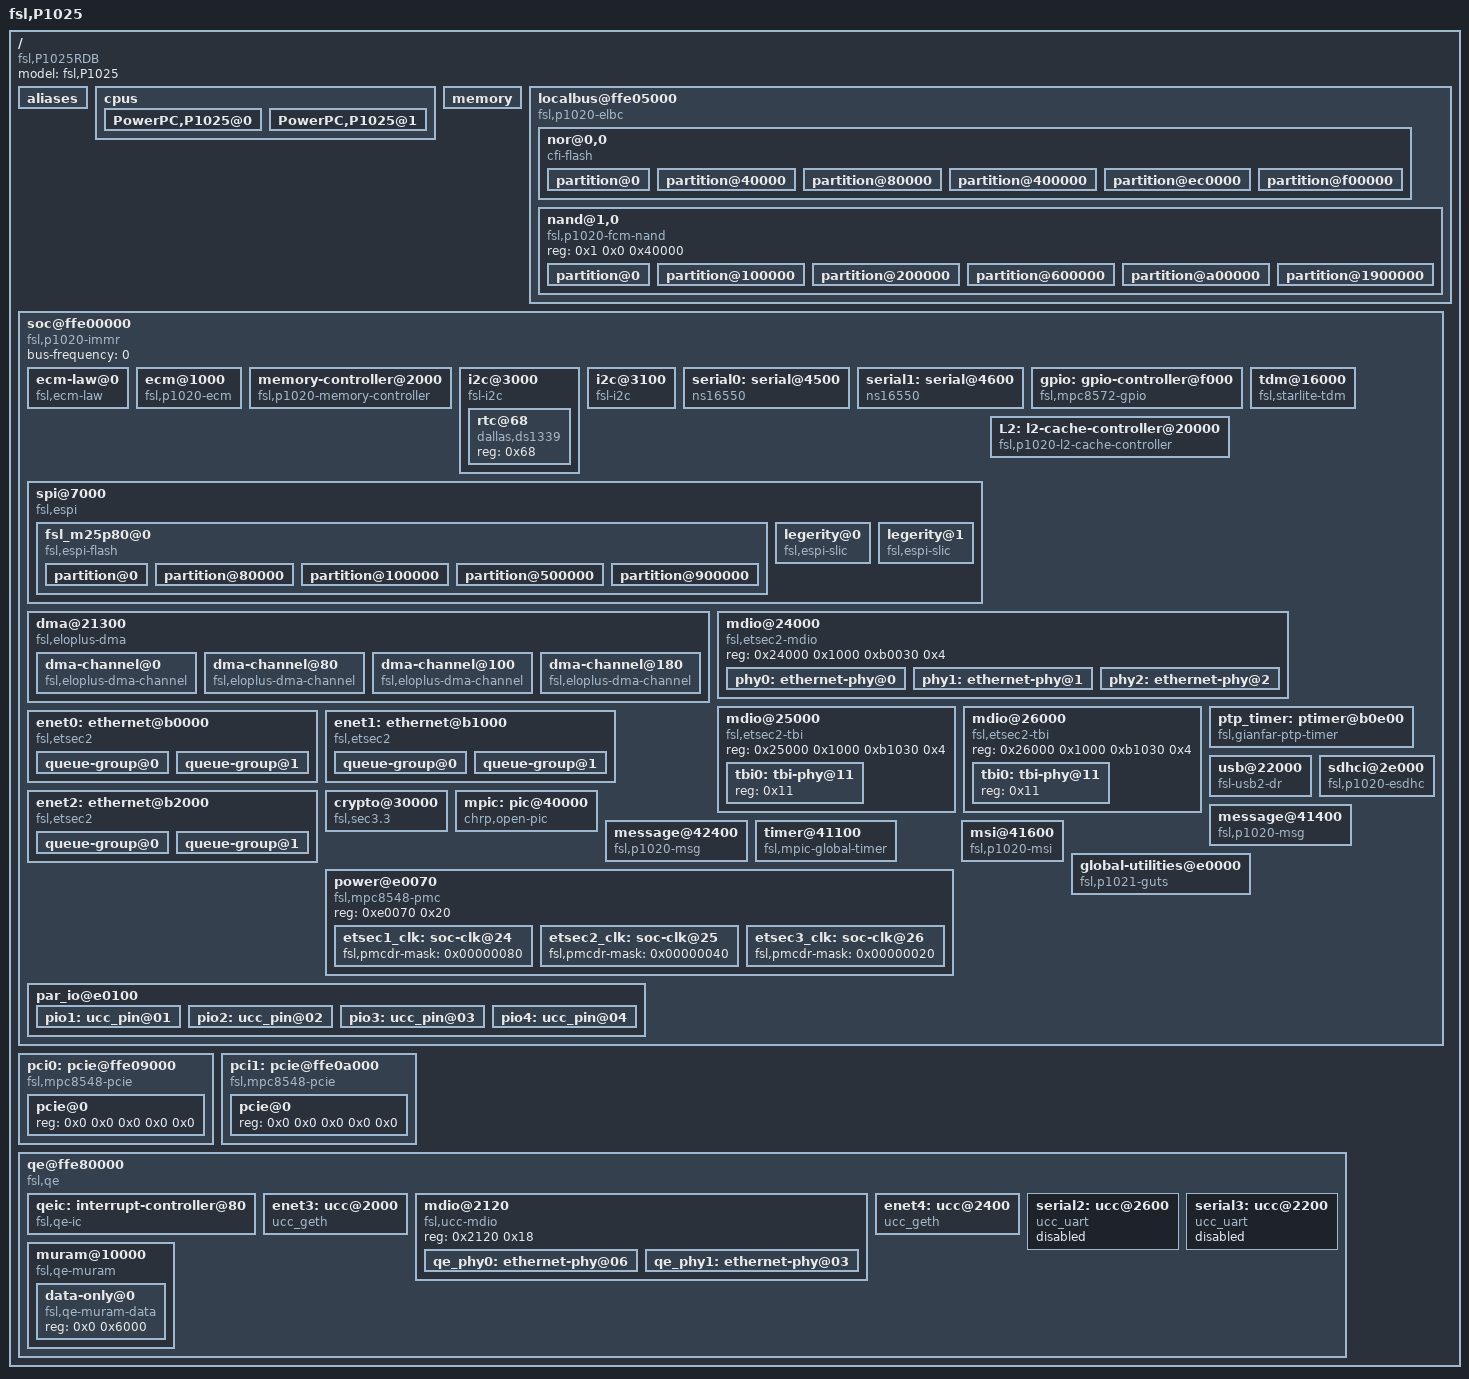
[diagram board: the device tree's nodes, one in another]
/*
 * P1025 RDB Device Tree Source
 *
 * Copyright 2009-2011 Freescale Semiconductor Inc.
 *
 * This program is free software; you can redistribute  it and/or modify it
 * under  the terms of  the GNU General  Public License as published by the
 * Free Software Foundation;  either version 2 of the  License, or (at your
 * option) any later version.
 */

/dts-v1/;
/ {
	model = "fsl,P1025";
	compatible = "fsl,P1025RDB";
	#address-cells = <2>;
	#size-cells = <2>;

	aliases {
		serial0 = &serial0;
		serial1 = &serial1;
		serial2 = &serial2;
		serial3 = &serial3;
		ethernet0 = &enet0;
		ethernet1 = &enet1;
		ethernet2 = &enet2;
		ethernet3 = &enet3;
		ethernet4 = &enet4;
		pci0 = &pci0;
		pci1 = &pci1;
	};

	cpus {
		#address-cells = <1>;
		#size-cells = <0>;

		PowerPC,P1025@0 {
			device_type = "cpu";
			reg = <0x0>;
			next-level-cache = <&L2>;
		};

		PowerPC,P1025@1 {
			device_type = "cpu";
			reg = <0x1>;
			next-level-cache = <&L2>;
		};
	};

	memory {
		device_type = "memory";
	};

	localbus@ffe05000 {
		#address-cells = <2>;
		#size-cells = <1>;
		compatible = "fsl,p1020-elbc", "fsl,elbc", "simple-bus";
		reg = <0 0xffe05000 0 0x1000>;
		interrupts = <19 2>;
		interrupt-parent = <&mpic>;

		/* NOR, NAND Flashes and Vitesse 5 port L2 switch */
		ranges = <0x0 0x0 0x0 0xef000000 0x01000000
			  0x1 0x0 0x0 0xff800000 0x00040000>;

		nor@0,0 {
			#address-cells = <1>;
			#size-cells = <1>;
			compatible = "cfi-flash";
			reg = <0x0 0x0 0x1000000>;
			bank-width = <2>;
			device-width = <1>;

			partition@0 {
				/* This location must not be altered  */
				/* 256KB for Vitesse 7385 Switch firmware */
				reg = <0x0 0x00040000>;
				label = "NOR Vitesse-7385 Firmware";
				read-only;
			};

			partition@40000 {
				/* 256KB for DTB Image */
				reg = <0x00040000 0x00040000>;
				label = "NOR DTB Image";
			};

			partition@80000 {
				/* 3.5 MB for Linux Kernel Image */
				reg = <0x00080000 0x00380000>;
				label = "NOR Linux Kernel Image";
			};

			partition@400000 {
				/* 10.75MB for JFFS2 based Root file System */
				reg = <0x00400000 0x00ac0000>;
				label = "NOR JFFS2 Root File System";
			};

			partition@ec0000 {
				/* 256KB for QE microcode image */
				reg = <0x00ec0000 0x00040000>;
				label = "Quicc Engine Microcode Image";
				read-only;
			};

			partition@f00000 {
				/* This location must not be altered  */
				/* 512KB for u-boot Bootloader Image */
				/* 512KB for u-boot Environment Variables */
				reg = <0x00f00000 0x00100000>;
				label = "NOR U-Boot Image";
				read-only;
			};
		};

		nand@1,0 {
			#address-cells = <1>;
			#size-cells = <1>;
			compatible = "fsl,p1020-fcm-nand",
				     "fsl,elbc-fcm-nand";
			reg = <0x1 0x0 0x40000>;

			partition@0 {
				/* This location must not be altered  */
				/* 1MB for u-boot Bootloader Image */
				reg = <0x0 0x00100000>;
				label = "NAND U-Boot Image";
				read-only;
			};

			partition@100000 {
				/* 1MB for DTB Image */
				reg = <0x00100000 0x00100000>;
				label = "NAND DTB Image";
			};

			partition@200000 {
				/* 4MB for Linux Kernel Image */
				reg = <0x00200000 0x00400000>;
				label = "NAND Linux Kernel Image";
			};

			partition@600000 {
				/* 4MB for Compressed Root file System Image */
				reg = <0x00600000 0x00400000>;
				label = "NAND Compressed RFS Image";
			};

			partition@a00000 {
				/* 15MB for JFFS2 based Root file System */
				reg = <0x00a00000 0x00f00000>;
				label = "NAND JFFS2 Root File System";
			};

			partition@1900000 {
				/* 7MB for User Writable Area */
				reg = <0x01900000 0x00700000>;
				label = "NAND Writable User area";
			};
		};

	};

	soc@ffe00000 {
		#address-cells = <1>;
		#size-cells = <1>;
		device_type = "soc";
		compatible = "fsl,p1020-immr", "simple-bus";
		ranges = <0x0  0x0 0xffe00000 0x100000>;
		bus-frequency = <0>;		// Filled out by uboot.

		ecm-law@0 {
			compatible = "fsl,ecm-law";
			reg = <0x0 0x1000>;
			fsl,num-laws = <12>;
		};

		ecm@1000 {
			compatible = "fsl,p1020-ecm", "fsl,ecm";
			reg = <0x1000 0x1000>;
			interrupts = <16 2>;
			interrupt-parent = <&mpic>;
		};

		memory-controller@2000 {
			compatible = "fsl,p1020-memory-controller";
			reg = <0x2000 0x1000>;
			interrupt-parent = <&mpic>;
			interrupts = <16 2>;
		};

		i2c@3000 {
			#address-cells = <1>;
			#size-cells = <0>;
			compatible = "fsl-i2c";
			reg = <0x3000 0x100>;
			interrupts = <43 2>;
			interrupt-parent = <&mpic>;
			dfsrr;
			rtc@68 {
				compatible = "dallas,ds1339";
				reg = <0x68>;
			};
		};

		i2c@3100 {
			#address-cells = <1>;
			#size-cells = <0>;
			compatible = "fsl-i2c";
			reg = <0x3100 0x100>;
			interrupts = <43 2>;
			interrupt-parent = <&mpic>;
			dfsrr;
		};

		serial0: serial@4500 {
			device_type = "serial";
			compatible = "ns16550";
			reg = <0x4500 0x100>;
			clock-frequency = <0>;
			interrupts = <42 2>;
			interrupt-parent = <&mpic>;
		};

		serial1: serial@4600 {
			device_type = "serial";
			compatible = "ns16550";
			reg = <0x4600 0x100>;
			clock-frequency = <0>;
			interrupts = <42 2>;
			interrupt-parent = <&mpic>;
		};

		spi@7000 {
			cell-index = <0>;
			#address-cells = <1>;
			#size-cells = <0>;
			compatible = "fsl,espi";
			reg = <0x7000 0x1000>;
			interrupts = <59 0x2>;
			interrupt-parent = <&mpic>;
			espi,num-ss-bits = <4>;
			mode = "cpu";

			fsl_m25p80@0 {
				#address-cells = <1>;
				#size-cells = <1>;
				compatible = "fsl,espi-flash";
				reg = <0>;
				linux,modalias = "fsl_m25p80";
				spi-max-frequency = <40000000>;

				partition@0 {
					/* 512KB for u-boot Bootloader Image */
					reg = <0x0 0x00080000>;
					label = "SPI U-Boot Image";
					read-only;
				};

				partition@80000 {
					/* 512KB for DTB Image */
					reg = <0x00080000 0x00080000>;
					label = "SPI DTB Image";
				};

				partition@100000 {
					/* 4MB for Linux Kernel Image */
					reg = <0x00100000 0x00400000>;
					label = "SPI Linux Kernel Image";
				};

				partition@500000 {
					/* 4MB for Compressed RFS Image */
					reg = <0x00500000 0x00400000>;
					label = "SPI Compressed RFS Image";
				};

				partition@900000 {
					/* 7MB for JFFS2 based RFS */
					reg = <0x00900000 0x00700000>;
					label = "SPI JFFS2 RFS";
				};
			};

			legerity@0{
				compatible = "fsl,espi-slic";
				reg = <1>;
				linux,modalias = "legerity";
				spi-max-frequency = <8000000>;
				ch1-rx-slot = <0>;
				ch1-tx-slot = <0>;
				ch2-rx-slot = <2>;
				ch2-tx-slot = <2>;
			};

			legerity@1{
				compatible = "fsl,espi-slic";
				reg = <2>;
				linux,modalias = "legerity";
				spi-max-frequency = <8000000>;
				ch1-rx-slot = <4>;
				ch1-tx-slot = <4>;
				ch2-rx-slot = <6>;
				ch2-tx-slot = <6>;
			};
		};

		gpio: gpio-controller@f000 {
			#gpio-cells = <2>;
			compatible = "fsl,mpc8572-gpio";
			reg = <0xf000 0x100>;
			interrupts = <47 0x2>;
			interrupt-parent = <&mpic>;
			gpio-controller;
		};

		tdm@16000 {
			compatible = "fsl,starlite-tdm";
			reg = <0x16000 0x200 0x2c000 0x2000>;
			clock-frequency = <0>;
			interrupts = <63 8 62 8>;
			interrupt-parent = < &mpic >;
		};

		L2: l2-cache-controller@20000 {
			compatible = "fsl,p1020-l2-cache-controller";
			reg = <0x20000 0x1000>;
			cache-line-size = <32>;	// 32 bytes
			cache-size = <0x40000>; // L2,256K
			interrupt-parent = <&mpic>;
			interrupts = <16 2>;
		};

		dma@21300 {
			#address-cells = <1>;
			#size-cells = <1>;
			compatible = "fsl,eloplus-dma";
			reg = <0x21300 0x4>;
			ranges = <0x0 0x21100 0x200>;
			cell-index = <0>;
			dma-channel@0 {
				compatible = "fsl,eloplus-dma-channel";
				reg = <0x0 0x80>;
				cell-index = <0>;
				interrupt-parent = <&mpic>;
				interrupts = <20 2>;
			};
			dma-channel@80 {
				compatible = "fsl,eloplus-dma-channel";
				reg = <0x80 0x80>;
				cell-index = <1>;
				interrupt-parent = <&mpic>;
				interrupts = <21 2>;
			};
			dma-channel@100 {
				compatible = "fsl,eloplus-dma-channel";
				reg = <0x100 0x80>;
				cell-index = <2>;
				interrupt-parent = <&mpic>;
				interrupts = <22 2>;
			};
			dma-channel@180 {
				compatible = "fsl,eloplus-dma-channel";
				reg = <0x180 0x80>;
				cell-index = <3>;
				interrupt-parent = <&mpic>;
				interrupts = <23 2>;
			};
		};

		mdio@24000 {
			#address-cells = <1>;
			#size-cells = <0>;
			compatible = "fsl,etsec2-mdio";
			reg = <0x24000 0x1000 0xb0030 0x4>;

			phy0: ethernet-phy@0 {
				interrupt-parent = <&mpic>;
				interrupts = <3 1>;
				reg = <0x0>;
			};

			phy1: ethernet-phy@1 {
				interrupt-parent = <&mpic>;
				interrupts = <2 1>;
				reg = <0x1>;
			};
			phy2: ethernet-phy@2 {
				interrupt-parent = <&mpic>;
				interrupts = <1 1>;
				reg = <0x2>;
			};
		};

		mdio@25000 {
			#address-cells = <1>;
			#size-cells = <0>;
			compatible = "fsl,etsec2-tbi";
			reg = <0x25000 0x1000 0xb1030 0x4>;

			tbi0: tbi-phy@11 {
				reg = <0x11>;
				device_type = "tbi-phy";
			};
		};

		mdio@26000 {
			#address-cells = <1>;
			#size-cells = <0>;
			compatible = "fsl,etsec2-tbi";
			reg = <0x26000 0x1000 0xb1030 0x4>;

			tbi0: tbi-phy@11 {
				reg = <0x11>;
				device_type = "tbi-phy";
			};
		};

		ptp_timer: ptimer@b0e00 {
			compatible = "fsl,gianfar-ptp-timer";
			reg = <0xb0e00 0xb0>;
			interrupts = <68 2 69 2 70 2>;
			interrupt-parent = <&mpic>;
			tmr-prsc = <0x2>;
			cksel = <1>;
		};

		enet0: ethernet@b0000 {
			#address-cells = <1>;
			#size-cells = <1>;
			device_type = "network";
			model = "eTSEC";
			compatible = "fsl,etsec2";
			fsl,num_rx_queues = <0x8>;
			fsl,num_tx_queues = <0x8>;
			local-mac-address = [ 00 00 00 00 00 00 ];
			interrupt-parent = <&mpic>;
			fixed-link = <1 1 1000 0 0>;
			phy-handle = <&phy2>;
			phy-connection-type = "rgmii-id";
			ptimer-handle = <&ptp_timer>;
			fsl,magic-packet;
			clk-handle = <&etsec1_clk>;

			queue-group@0 {
				#address-cells = <1>;
				#size-cells = <1>;
				reg = <0xb0000 0x1000>;
				interrupts = <29 2 30 2 34 2>;
			};

			queue-group@1 {
				#address-cells = <1>;
				#size-cells = <1>;
				reg = <0xb4000 0x1000>;
				interrupts = <17 2 18 2 24 2>;
			};
		};

		enet1: ethernet@b1000 {
			#address-cells = <1>;
			#size-cells = <1>;
			device_type = "network";
			model = "eTSEC";
			compatible = "fsl,etsec2";
			fsl,num_rx_queues = <0x8>;
			fsl,num_tx_queues = <0x8>;
			local-mac-address = [ 00 00 00 00 00 00 ];
			interrupt-parent = <&mpic>;
			phy-handle = <&phy0>;
			tbi-handle = <&tbi0>;
			phy-connection-type = "sgmii";
			ptimer-handle = <&ptp_timer>;
			fsl,magic-packet;
			clk-handle = <&etsec2_clk>;

			queue-group@0 {
				#address-cells = <1>;
				#size-cells = <1>;
				reg = <0xb1000 0x1000>;
				interrupts = <35 2 36 2 40 2>;
			};

			queue-group@1 {
				#address-cells = <1>;
				#size-cells = <1>;
				reg = <0xb5000 0x1000>;
				interrupts = <51 2 52 2 67 2>;
			};
		};

		enet2: ethernet@b2000 {
			#address-cells = <1>;
			#size-cells = <1>;
			device_type = "network";
			model = "eTSEC";
			compatible = "fsl,etsec2";
			fsl,num_rx_queues = <0x8>;
			fsl,num_tx_queues = <0x8>;
			local-mac-address = [ 00 00 00 00 00 00 ];
			interrupt-parent = <&mpic>;
			phy-handle = <&phy1>;
			phy-connection-type = "rgmii-id";
			ptimer-handle = <&ptp_timer>;
			fsl,magic-packet;
			clk-handle = <&etsec3_clk>;

			queue-group@0 {
				#address-cells = <1>;
				#size-cells = <1>;
				reg = <0xb2000 0x1000>;
				interrupts = <31 2 32 2 33 2>;
			};

			queue-group@1 {
				#address-cells = <1>;
				#size-cells = <1>;
				reg = <0xb6000 0x1000>;
				interrupts = <25 2 26 2 27 2>;
			};
		};

		usb@22000 {
			#address-cells = <1>;
			#size-cells = <0>;
			compatible = "fsl-usb2-dr";
			reg = <0x22000 0x1000>;
			interrupt-parent = <&mpic>;
			interrupts = <28 0x2>;
			phy_type = "ulpi";
		};

		sdhci@2e000 {
			compatible = "fsl,p1020-esdhc", "fsl,esdhc";
			reg = <0x2e000 0x1000>;
			interrupts = <72 0x2>;
			interrupt-parent = <&mpic>;
			/* Filled in by U-Boot */
			clock-frequency = <0>;
		};

		crypto@30000 {
			compatible = "fsl,sec3.3", "fsl,sec3.1",
				     "fsl,sec3.0", "fsl,sec2.4",
				     "fsl,sec2.2", "fsl,sec2.1", "fsl,sec2.0";
			reg = <0x30000 0x10000>;
			interrupts = <45 2 58 2>;
			interrupt-parent = <&mpic>;
			fsl,num-channels = <4>;
			fsl,channel-fifo-len = <24>;
			fsl,exec-units-mask = <0x97c>;
			fsl,descriptor-types-mask = <0x3a30abf>;
			fsl,multi-host-mode = "dual";
			fsl,channel-remap = <0x3>;
		};

		mpic: pic@40000 {
			interrupt-controller;
			#address-cells = <0>;
			#interrupt-cells = <2>;
			reg = <0x40000 0x40000>;
			compatible = "chrp,open-pic";
			device_type = "open-pic";
		};

		message@41400 {
			compatible = "fsl,p1020-msg", "fsl,mpic-msg";
			reg = <0x41400 0x200>;
			interrupts = <
				0xb0 2
				0xb1 2
				0xb2 2
				0xb3 2>;
			interrupt-parent = <&mpic>;
		};

		message@42400 {
			compatible = "fsl,p1020-msg", "fsl,mpic-msg";
			reg = <0x42400 0x200>;
			interrupts = <
				0xb4 2
				0xb5 2
				0xb6 2
				0xb7 2>;
			interrupt-parent = <&mpic>;
		};

		timer@41100 {
			compatible = "fsl,mpic-global-timer";
			reg = <0x41100 0x204>;
			interrupts = <0xf7 0x2>;
			interrupt-parent = <&mpic>;
		};

		power@e0070{
			compatible = "fsl,mpc8548-pmc";
			reg = <0xe0070 0x20>;

			etsec1_clk: soc-clk@24{
				fsl,pmcdr-mask = <0x00000080>;
			};
			etsec2_clk: soc-clk@25{
				fsl,pmcdr-mask = <0x00000040>;
			};
			etsec3_clk: soc-clk@26{
				fsl,pmcdr-mask = <0x00000020>;
			};
		};

		msi@41600 {
			compatible = "fsl,p1020-msi", "fsl,mpic-msi";
			reg = <0x41600 0x80>;
			msi-available-ranges = <0 0x100>;
			interrupts = <
				0xe0 0
				0xe1 0
				0xe2 0
				0xe3 0
				0xe4 0
				0xe5 0
				0xe6 0
				0xe7 0>;
			interrupt-parent = <&mpic>;
		};

		global-utilities@e0000 {        //global utilities block
			compatible = "fsl,p1021-guts";
			reg = <0xe0000 0x1000>;
			fsl,has-rstcr;
		};

		par_io@e0100 {
			#address-cells = <1>;
			#size-cells = <1>;
			reg = <0xe0100 0x60>;
			ranges = <0x0 0xe0100 0x60>;
			device_type = "par_io";
			num-ports = <3>;
			pio1: ucc_pin@01 {
				pio-map = <
			/* port  pin  dir  open_drain  assignment  has_irq */
					0x1  0x13 0x1  0x0  0x1  0x0    /* QE_MUX_MDC */
					0x1  0x14 0x3  0x0  0x1  0x0    /* QE_MUX_MDIO */
					0x0  0x17 0x2  0x0  0x2  0x0    /* CLK12 */
					0x0  0x18 0x2  0x0  0x1  0x0    /* CLK9 */
					0x0  0x7  0x1  0x0  0x2  0x0    /* ENET1_TXD0_SER1_TXD0 */
					0x0  0x9  0x1  0x0  0x2  0x0    /* ENET1_TXD1_SER1_TXD1 */
					0x0  0xb  0x1  0x0  0x2  0x0    /* ENET1_TXD2_SER1_TXD2 */
					0x0  0xc  0x1  0x0  0x2  0x0    /* ENET1_TXD3_SER1_TXD3 */
					0x0  0x6  0x2  0x0  0x2  0x0    /* ENET1_RXD0_SER1_RXD0 */
					0x0  0xa  0x2  0x0  0x2  0x0    /* ENET1_RXD1_SER1_RXD1 */
					0x0  0xe  0x2  0x0  0x2  0x0    /* ENET1_RXD2_SER1_RXD2 */
					0x0  0xf  0x2  0x0  0x2  0x0    /* ENET1_RXD3_SER1_RXD3 */
					0x0  0x5  0x1  0x0  0x2  0x0    /* ENET1_TX_EN_SER1_RTS_B */
					0x0  0xd  0x1  0x0  0x2  0x0    /* ENET1_TX_ER */
					0x0  0x4  0x2  0x0  0x2  0x0    /* ENET1_RX_DV_SER1_CTS_B */
					0x0  0x8  0x2  0x0  0x2  0x0    /* ENET1_RX_ER_SER1_CD_B */
					0x0  0x11 0x2  0x0  0x2  0x0    /* ENET1_CRS */
					0x0  0x10 0x2  0x0  0x2  0x0>;    /* ENET1_COL */
			};

			pio2: ucc_pin@02 {
				pio-map = <
			/* port  pin  dir  open_drain  assignment  has_irq */
					0x1  0x13 0x1  0x0  0x1  0x0    /* QE_MUX_MDC */
					0x1  0x14 0x3  0x0  0x1  0x0    /* QE_MUX_MDIO */
					0x1  0xb  0x2  0x0  0x1  0x0    /* CLK13 */
					0x1  0x7  0x1  0x0  0x2  0x0    /* ENET5_TXD0_SER5_TXD0 */
					0x1  0xa  0x1  0x0  0x2  0x0    /* ENET5_TXD1_SER5_TXD1 */
					0x1  0x6  0x2  0x0  0x2  0x0    /* ENET5_RXD0_SER5_RXD0 */
					0x1  0x9  0x2  0x0  0x2  0x0    /* ENET5_RXD1_SER5_RXD1 */
					0x1  0x5  0x1  0x0  0x2  0x0    /* ENET5_TX_EN_SER5_RTS_B */
					0x1  0x4  0x2  0x0  0x2  0x0    /* ENET5_RX_DV_SER5_CTS_B */
					0x1  0x8  0x2  0x0  0x2  0x0>;    /* ENET5_RX_ER_SER5_CD_B */
			};

			pio3: ucc_pin@03 {
				pio-map = <
			/* port  pin  dir  open_drain  assignment  has_irq */
					0x0  0x16 0x2  0x0  0x2  0x0    /* SER7_CD_B*/
					0x0  0x12 0x2  0x0  0x2  0x0    /* SER7_CTS_B*/
					0x0  0x13 0x1  0x0  0x2  0x0    /* SER7_RTS_B*/
					0x0  0x14 0x2  0x0  0x2  0x0    /* SER7_RXD0*/
					0x0  0x15 0x1  0x0  0x2  0x0>;    /* SER7_TXD0*/
			};

			pio4: ucc_pin@04 {
				pio-map = <
			/* port  pin  dir  open_drain  assignment  has_irq */
					0x1  0x0  0x2  0x0  0x2  0x0    /* SER3_CD_B*/
					0x0  0x1c 0x2  0x0  0x2  0x0    /* SER3_CTS_B*/
					0x0  0x1d 0x1  0x0  0x2  0x0    /* SER3_RTS_B*/
					0x0  0x1e 0x2  0x0  0x2  0x0    /* SER3_RXD0*/
					0x0  0x1f 0x1  0x0  0x2  0x0>;    /* SER3_TXD0*/
			};
		};
	};

	pci0: pcie@ffe09000 {
		compatible = "fsl,mpc8548-pcie";
		cell-index = <2>;
		device_type = "pci";
		#interrupt-cells = <1>;
		#size-cells = <2>;
		#address-cells = <3>;
		reg = <0 0xffe09000 0 0x1000>;
		bus-range = <0 255>;
		ranges = <0x2000000 0x0 0xa0000000 0 0xa0000000 0x0 0x20000000
			  0x1000000 0x0 0x00000000 0 0xffc10000 0x0 0x10000>;
		clock-frequency = <33333333>;
		interrupt-parent = <&mpic>;
		interrupts = <16 2>;
		interrupt-map-mask = <0xf800 0x0 0x0 0x7>;
		interrupt-map = <
			/* IDSEL 0x0 */
			0000 0x0 0x0 0x1 &mpic 0x4 0x1
			0000 0x0 0x0 0x2 &mpic 0x5 0x1
			0000 0x0 0x0 0x3 &mpic 0x6 0x1
			0000 0x0 0x0 0x4 &mpic 0x7 0x1
			>;
		pcie@0 {
			reg = <0x0 0x0 0x0 0x0 0x0>;
			#size-cells = <2>;
			#address-cells = <3>;
			device_type = "pci";
			ranges = <0x2000000 0x0 0xa0000000
				  0x2000000 0x0 0xa0000000
				  0x0 0x20000000

				  0x1000000 0x0 0x0
				  0x1000000 0x0 0x0
				  0x0 0x100000>;
		};
	};

	pci1: pcie@ffe0a000 {
		compatible = "fsl,mpc8548-pcie";
		cell-index = <1>;
		device_type = "pci";
		#interrupt-cells = <1>;
		#size-cells = <2>;
		#address-cells = <3>;
		reg = <0 0xffe0a000 0 0x1000>;
		bus-range = <0 255>;
		ranges = <0x2000000 0x0 0x80000000 0 0x80000000 0x0 0x20000000
			  0x1000000 0x0 0x00000000 0 0xffc00000 0x0 0x10000>;
		clock-frequency = <33333333>;
		interrupt-parent = <&mpic>;
		interrupts = <16 2>;
		interrupt-map-mask = <0xf800 0x0 0x0 0x7>;
		interrupt-map = <
			/* IDSEL 0x0 */
			0000 0x0 0x0 0x1 &mpic 0x0 0x1
			0000 0x0 0x0 0x2 &mpic 0x1 0x1
			0000 0x0 0x0 0x3 &mpic 0x2 0x1
			0000 0x0 0x0 0x4 &mpic 0x3 0x1
			>;
		pcie@0 {
			reg = <0x0 0x0 0x0 0x0 0x0>;
			#size-cells = <2>;
			#address-cells = <3>;
			device_type = "pci";
			ranges = <0x2000000 0x0 0x80000000
				  0x2000000 0x0 0x80000000
				  0x0 0x20000000

				  0x1000000 0x0 0x0
				  0x1000000 0x0 0x0
				  0x0 0x100000>;
		};
	};

	qe@ffe80000 {
		#address-cells = <1>;
		#size-cells = <1>;
		device_type = "qe";
		compatible = "fsl,qe";
		ranges = <0x0 0x0 0xffe80000 0x40000>;
		reg = <0 0xffe80000 0 0x480>;
		brg-frequency = <0>;
		bus-frequency = <0>;
		fsl,qe-num-riscs = <1>;
		fsl,qe-num-snums = <28>;
		fsl,time-stamp1-clock = "qeclk";
		fsl,time-stamp2-clock = "qeclk";

		qeic: interrupt-controller@80 {
			interrupt-controller;
			compatible = "fsl,qe-ic";
			#address-cells = <0>;
			#interrupt-cells = <1>;
			reg = <0x80 0x80>;
			interrupts = <63 2 60 2>; //high:47 low:44
			interrupt-parent = <&mpic>;
		};

		enet3: ucc@2000 {
			device_type = "network";
			compatible = "ucc_geth";
			cell-index = <1>;
			reg = <0x2000 0x200>;
			interrupts = <32>;
			interrupt-parent = <&qeic>;
			local-mac-address = [ 00 00 00 00 00 00 ];
			rx-clock-name = "clk12";
			tx-clock-name = "clk9";
			pio-handle = <&pio1>;
			phy-handle = <&qe_phy0>;
			phy-connection-type = "mii";
		};

		mdio@2120 {
			#address-cells = <1>;
			#size-cells = <0>;
			reg = <0x2120 0x18>;
			compatible = "fsl,ucc-mdio";

			qe_phy0: ethernet-phy@06 {
				interrupt-parent = <&mpic>;
				interrupts = <4 1>;
				reg = <0x6>;
				device_type = "ethernet-phy";
			};
			qe_phy1: ethernet-phy@03 {
				interrupt-parent = <&mpic>;
				interrupts = <5 1>;
				reg = <0x3>;
				device_type = "ethernet-phy";
			};
		};

		enet4: ucc@2400 {
			device_type = "network";
			compatible = "ucc_geth";
			cell-index = <5>;
			reg = <0x2400 0x200>;
			interrupts = <40>;
			interrupt-parent = <&qeic>;
			local-mac-address = [ 00 00 00 00 00 00 ];
			rx-clock-name = "none";
			tx-clock-name = "clk13";
			pio-handle = <&pio2>;
			phy-handle = <&qe_phy1>;
			phy-connection-type = "rmii";
		};

		serial2: ucc@2600 {
			device_type = "serial";
			compatible = "ucc_uart";
			status = "disabled";
			reg = <0x2600 0x200>;
			cell-index = <7>;
			port-number = <0>;
			rx-clock-name = "brg6";
			tx-clock-name = "brg6";
			interrupts = <42>;
			interrupt-parent = <&qeic>;
			pio-handle = <&pio3>;
		};

		serial3: ucc@2200 {
			device_type = "serial";
			compatible = "ucc_uart";
			status = "disabled";
			reg = <0x2200 0x200>;
			cell-index = <3>;
			port-number = <1>;
			rx-clock-name = "brg2";
			tx-clock-name = "brg2";
			interrupts = <34>;
			interrupt-parent = <&qeic>;
			pio-handle = <&pio4>;
		};

		muram@10000 {
			#address-cells = <1>;
			#size-cells = <1>;
			compatible = "fsl,qe-muram", "fsl,cpm-muram";
			ranges = <0x0 0x10000 0x6000>;

			data-only@0 {
				compatible = "fsl,qe-muram-data",
				"fsl,cpm-muram-data";
				reg = <0x0 0x6000>;
			};
		};
	};
};
